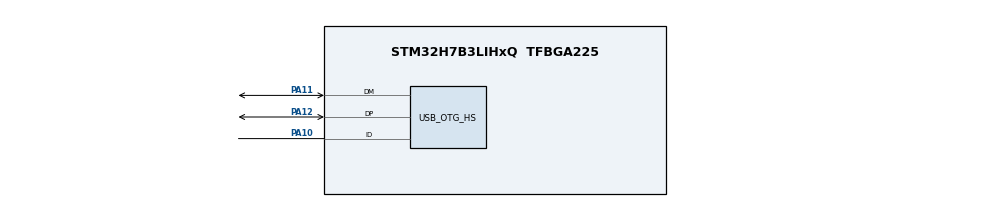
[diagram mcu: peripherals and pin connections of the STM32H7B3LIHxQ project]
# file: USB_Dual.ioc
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Mcu.Family=STM32H7
Mcu.Name=STM32H7B3LIHxQ
Mcu.Package=TFBGA225
NVIC.PriorityGroup=NVIC_PRIORITYGROUP_4
NVIC.TIM17_IRQn=true\:15\:0\:false\:false\:true\:false\:false\:true\:true
NVIC.TimeBase=TIM17_IRQn
NVIC.TimeBaseIP=TIM17
PA10.Mode=OTG/Dual-Role-Device-FS
PA10.Signal=USB_OTG_HS_ID
PA11.Mode=OTG/Dual-Role-Device-FS
PA11.Signal=USB_OTG_HS_DM
PA12.Mode=OTG/Dual-Role-Device-FS
PA12.Signal=USB_OTG_HS_DP
PH0-OSC_IN.Mode=HSE-External-Oscillator
PH0-OSC_IN.Signal=RCC_OSC_IN
PH1-OSC_OUT.Mode=HSE-External-Oscillator
PH1-OSC_OUT.Signal=RCC_OSC_OUT
ProjectManager.HeapSize=0x2000
ProjectManager.StackSize=0x400
ProjectManager.TargetToolchain=STM32CubeIDE
RCC.ADCFreq_Value=16125000
RCC.APB1Freq_Value=140000000
RCC.APB2Freq_Value=140000000
RCC.APB3Freq_Value=140000000
RCC.APB4Freq_Value=140000000
RCC.CDPPRE=RCC_APB3_DIV2
RCC.CDPPRE1=RCC_APB1_DIV2
RCC.CDPPRE2=RCC_APB2_DIV2
RCC.CortexFreq_Value=280000000
RCC.DIVM1=2
RCC.DIVM3=4
RCC.DIVN1=140
RCC.DIVN3=96
RCC.DIVQ3=4
RCC.HCLKFreq_Value=280000000
RCC.HSE_VALUE=8000000
RCC.PLL2FRACN=0
RCC.PLL3FRACN=0
RCC.PLLFRACN=0
RCC.SRDPPRE=RCC_APB4_DIV2
RCC.SYSCLKFreq_VALUE=280000000
RCC.SYSCLKSource=RCC_SYSCLKSOURCE_PLLCLK
RCC.USBCLockSelection=RCC_USBCLKSOURCE_PLL3
RCC.USBFreq_Value=48000000
STMicroelectronics.X-CUBE-AZRTOS-H7.2.1.0.ThreadXCcRTOSJjThreadXJjCore=true
STMicroelectronics.X-CUBE-AZRTOS-H7.2.1.0.USBD_CDCACM_EPIN_ADDR=2
STMicroelectronics.X-CUBE-AZRTOS-H7.2.1.0.USBXCcUSBJjUSBXJjCoreSystem=true
STMicroelectronics.X-CUBE-AZRTOS-H7.2.1.0.USBXCcUSBJjUSBXJjUXOoDeviceOoClassOoCDCOoACM=true
STMicroelectronics.X-CUBE-AZRTOS-H7.2.1.0.USBXCcUSBJjUSBXJjUXOoDeviceOoControllers=true
STMicroelectronics.X-CUBE-AZRTOS-H7.2.1.0.USBXCcUSBJjUSBXJjUXOoDeviceOoCoreStack=true
STMicroelectronics.X-CUBE-AZRTOS-H7.2.1.0.USBXCcUSBJjUSBXJjUXOoHostOoClassOoHIDOoCore=true
STMicroelectronics.X-CUBE-AZRTOS-H7.2.1.0.USBXCcUSBJjUSBXJjUXOoHostOoClassOoHIDOoMouse=true
STMicroelectronics.X-CUBE-AZRTOS-H7.2.1.0.USBXCcUSBJjUSBXJjUXOoHostOoControllers=true
STMicroelectronics.X-CUBE-AZRTOS-H7.2.1.0.USBXCcUSBJjUSBXJjUXOoHostOoCoreStack=true
STMicroelectronics.X-CUBE-AZRTOS-H7.2.1.0.UX_DEVICE_APP_MEM_POOL_SIZE=1024*64
STMicroelectronics.X-CUBE-AZRTOS-H7.2.1.0.UX_HOST_APP_MEM_POOL_SIZE=1024*128
STMicroelectronics.X-CUBE-AZRTOS-H7.2.1.0_IsAnAzureRtosMw=true
VP_STMicroelectronics.X-CUBE-AZRTOS-H7_VS_RTOSJjThreadX_6.1.10_2.1.0.Mode=RTOSJjThreadX
VP_STMicroelectronics.X-CUBE-AZRTOS-H7_VS_USBJjUSBX_6.1.10_2.1.0.Mode=USBJjUSBX
VP_SYS_VS_tim17.Mode=TIM17
board=custom

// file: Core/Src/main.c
/* USER CODE BEGIN Header */
/**
  ******************************************************************************
  * @file           : main.c
  * @brief          : Main program body
  ******************************************************************************
  * @attention
  *
  * Copyright (c) 2022 STMicroelectronics.
  * All rights reserved.
  *
  * This software is licensed under terms that can be found in the LICENSE file
  * in the root directory of this software component.
  * If no LICENSE file comes with this software, it is provided AS-IS.
  *
  ******************************************************************************
  */
/* USER CODE END Header */
#include "main.h"
#include "app_threadx.h"
#include "usb_otg.h"
#include "gpio.h"

void SystemClock_Config(void);

int main(void)
{
  /* USER CODE BEGIN 1 */
  {
      MPU_Region_InitTypeDef MPU_InitStruct = {0};

    /* Disables the MPU */
    HAL_MPU_Disable();

    /** Initializes and configures the Region and the memory to be protected
    */
    MPU_InitStruct.Enable = MPU_REGION_ENABLE;
    MPU_InitStruct.Number = MPU_REGION_NUMBER0;
    MPU_InitStruct.BaseAddress = 0x0;
    MPU_InitStruct.Size = MPU_REGION_SIZE_4GB;
    MPU_InitStruct.SubRegionDisable = 0x87;
    MPU_InitStruct.TypeExtField = MPU_TEX_LEVEL0;
    MPU_InitStruct.AccessPermission = MPU_REGION_NO_ACCESS;
    MPU_InitStruct.DisableExec = MPU_INSTRUCTION_ACCESS_DISABLE;
    MPU_InitStruct.IsShareable = MPU_ACCESS_SHAREABLE;
    MPU_InitStruct.IsCacheable = MPU_ACCESS_NOT_CACHEABLE;
    MPU_InitStruct.IsBufferable = MPU_ACCESS_NOT_BUFFERABLE;

    HAL_MPU_ConfigRegion(&MPU_InitStruct);
    /* Enables the MPU */
    HAL_MPU_Enable(MPU_PRIVILEGED_DEFAULT);
  }
  /* USER CODE END 1 */

  /* MCU Configuration--------------------------------------------------------*/

  /* Reset of all peripherals, Initializes the Flash interface and the Systick. */
  HAL_Init();

  /* Configure the system clock */
  SystemClock_Config();

  /* Initialize all configured peripherals */
  MX_GPIO_Init();
  MX_USB_OTG_HS_USB_Init();

  MX_ThreadX_Init();

  /* We should never get here as control is now taken by the scheduler */
  /* Infinite loop */
  while (1)
  {

  }
}

void SystemClock_Config(void)
{
  RCC_OscInitTypeDef RCC_OscInitStruct = {0};
  RCC_ClkInitTypeDef RCC_ClkInitStruct = {0};

  /*AXI clock gating */
  RCC->CKGAENR = 0xFFFFFFFF;

  /** Supply configuration update enable
  */
  HAL_PWREx_ConfigSupply(PWR_DIRECT_SMPS_SUPPLY);

  /** Configure the main internal regulator output voltage
  */
  __HAL_PWR_VOLTAGESCALING_CONFIG(PWR_REGULATOR_VOLTAGE_SCALE0);

  while(!__HAL_PWR_GET_FLAG(PWR_FLAG_VOSRDY)) {}

  /** Macro to configure the PLL clock source
  */
  __HAL_RCC_PLL_PLLSOURCE_CONFIG(RCC_PLLSOURCE_HSE);

  /** Initializes the RCC Oscillators according to the specified parameters
  * in the RCC_OscInitTypeDef structure.
  */
  RCC_OscInitStruct.OscillatorType = RCC_OSCILLATORTYPE_HSE;
  RCC_OscInitStruct.HSEState = RCC_HSE_ON;
  RCC_OscInitStruct.PLL.PLLState = RCC_PLL_ON;
  RCC_OscInitStruct.PLL.PLLSource = RCC_PLLSOURCE_HSE;
  RCC_OscInitStruct.PLL.PLLM = 2;
  RCC_OscInitStruct.PLL.PLLN = 140;
  RCC_OscInitStruct.PLL.PLLP = 2;
  RCC_OscInitStruct.PLL.PLLQ = 2;
  RCC_OscInitStruct.PLL.PLLR = 2;
  RCC_OscInitStruct.PLL.PLLRGE = RCC_PLL1VCIRANGE_2;
  RCC_OscInitStruct.PLL.PLLVCOSEL = RCC_PLL1VCOWIDE;
  RCC_OscInitStruct.PLL.PLLFRACN = 0;
  if (HAL_RCC_OscConfig(&RCC_OscInitStruct) != HAL_OK)
  {
    Error_Handler();
  }

  /** Initializes the CPU, AHB and APB buses clocks
  */
  RCC_ClkInitStruct.ClockType = RCC_CLOCKTYPE_HCLK|RCC_CLOCKTYPE_SYSCLK
                              |RCC_CLOCKTYPE_PCLK1|RCC_CLOCKTYPE_PCLK2
                              |RCC_CLOCKTYPE_D3PCLK1|RCC_CLOCKTYPE_D1PCLK1;
  RCC_ClkInitStruct.SYSCLKSource = RCC_SYSCLKSOURCE_PLLCLK;
  RCC_ClkInitStruct.SYSCLKDivider = RCC_SYSCLK_DIV1;
  RCC_ClkInitStruct.AHBCLKDivider = RCC_HCLK_DIV1;
  RCC_ClkInitStruct.APB3CLKDivider = RCC_APB3_DIV2;
  RCC_ClkInitStruct.APB1CLKDivider = RCC_APB1_DIV2;
  RCC_ClkInitStruct.APB2CLKDivider = RCC_APB2_DIV2;
  RCC_ClkInitStruct.APB4CLKDivider = RCC_APB4_DIV2;

  if (HAL_RCC_ClockConfig(&RCC_ClkInitStruct, FLASH_LATENCY_7) != HAL_OK)
  {
    Error_Handler();
  }
}

void HAL_TIM_PeriodElapsedCallback(TIM_HandleTypeDef *htim)
{
  if (htim->Instance == TIM17) {
    HAL_IncTick();
  }
}

void Error_Handler(void)
{
  __disable_irq();
  while (1)
  {
  }
}
